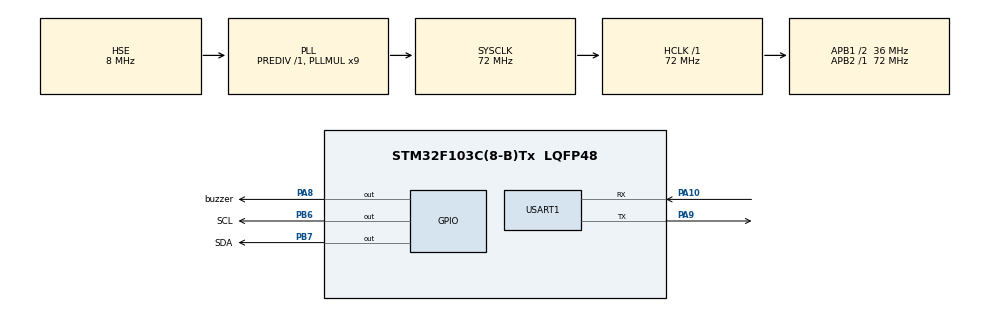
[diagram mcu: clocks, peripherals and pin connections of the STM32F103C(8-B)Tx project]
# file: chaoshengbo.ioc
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Dma.Request0=USART1_RX
Dma.Request1=USART1_TX
Dma.USART1_RX.0.Direction=DMA_PERIPH_TO_MEMORY
Dma.USART1_RX.0.Instance=DMA1_Channel5
Dma.USART1_RX.0.MemDataAlignment=DMA_MDATAALIGN_BYTE
Dma.USART1_RX.0.MemInc=DMA_MINC_ENABLE
Dma.USART1_RX.0.Mode=DMA_NORMAL
Dma.USART1_RX.0.PeriphDataAlignment=DMA_PDATAALIGN_BYTE
Dma.USART1_RX.0.PeriphInc=DMA_PINC_DISABLE
Dma.USART1_RX.0.Priority=DMA_PRIORITY_LOW
Dma.USART1_TX.1.Direction=DMA_MEMORY_TO_PERIPH
Dma.USART1_TX.1.Instance=DMA1_Channel4
Dma.USART1_TX.1.MemDataAlignment=DMA_MDATAALIGN_BYTE
Dma.USART1_TX.1.MemInc=DMA_MINC_ENABLE
Dma.USART1_TX.1.Mode=DMA_NORMAL
Dma.USART1_TX.1.PeriphDataAlignment=DMA_PDATAALIGN_BYTE
Dma.USART1_TX.1.PeriphInc=DMA_PINC_DISABLE
Dma.USART1_TX.1.Priority=DMA_PRIORITY_LOW
Mcu.Family=STM32F1
Mcu.Name=STM32F103C(8-B)Tx
Mcu.Package=LQFP48
NVIC.DMA1_Channel4_IRQn=true\:0\:0\:false\:false\:true\:false\:true\:true
NVIC.DMA1_Channel5_IRQn=true\:0\:0\:false\:false\:true\:false\:true\:true
NVIC.PriorityGroup=NVIC_PRIORITYGROUP_4
NVIC.TIM1_UP_IRQn=true\:1\:0\:true\:false\:true\:true\:true\:true
NVIC.USART1_IRQn=true\:2\:0\:true\:false\:true\:false\:true\:true
PA10.Mode=Asynchronous
PA10.Signal=USART1_RX
PA13.Mode=Serial_Wire
PA13.Signal=SYS_JTMS-SWDIO
PA14.Mode=Serial_Wire
PA14.Signal=SYS_JTCK-SWCLK
PA8.GPIO_Label=buzzer
PA8.PinState=GPIO_PIN_SET
PA8.Signal=GPIO_Output
PA9.Mode=Asynchronous
PA9.Signal=USART1_TX
PB6.GPIO_Label=SCL
PB6.GPIO_ModeDefaultOutputPP=GPIO_MODE_OUTPUT_OD
PB6.GPIO_PuPd=GPIO_NOPULL
PB6.PinState=GPIO_PIN_SET
PB6.Signal=GPIO_Output
PB7.GPIO_Label=SDA
PB7.GPIO_ModeDefaultOutputPP=GPIO_MODE_OUTPUT_OD
PB7.GPIO_PuPd=GPIO_NOPULL
PB7.PinState=GPIO_PIN_SET
PB7.Signal=GPIO_Output
PD0-OSC_IN.Mode=HSE-External-Oscillator
PD0-OSC_IN.Signal=RCC_OSC_IN
PD1-OSC_OUT.Mode=HSE-External-Oscillator
PD1-OSC_OUT.Signal=RCC_OSC_OUT
ProjectManager.HeapSize=0x200
ProjectManager.StackSize=0x400
ProjectManager.TargetToolchain=MDK-ARM V5.32
RCC.AHBFreq_Value=72000000
RCC.APB1CLKDivider=RCC_HCLK_DIV2
RCC.APB1Freq_Value=36000000
RCC.APB1TimFreq_Value=72000000
RCC.APB2Freq_Value=72000000
RCC.APB2TimFreq_Value=72000000
RCC.HCLKFreq_Value=72000000
RCC.PLLMUL=RCC_PLL_MUL9
RCC.PLLSourceVirtual=RCC_PLLSOURCE_HSE
RCC.SYSCLKFreq_VALUE=72000000
RCC.SYSCLKSource=RCC_SYSCLKSOURCE_PLLCLK
RCC.USBFreq_Value=72000000
TIM1.Period=1000-1
TIM1.Prescaler=72-1
USART1.VirtualMode=VM_ASYNC
VP_TIM1_VS_ClockSourceINT.Mode=Internal
board=custom

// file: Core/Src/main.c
/* USER CODE BEGIN Header */
/**
  ******************************************************************************
  * @file           : main.c
  * @brief          : Main program body
  ******************************************************************************
  * @attention
  *
  * Copyright (c) 2024 STMicroelectronics.
  * All rights reserved.
  *
  * This software is licensed under terms that can be found in the LICENSE file
  * in the root directory of this software component.
  * If no LICENSE file comes with this software, it is provided AS-IS.
  *
  ******************************************************************************
  */
/* USER CODE END Header */
#include "main.h"
#include "dma.h"
#include "tim.h"
#include "usart.h"
#include "gpio.h"

/* USER CODE BEGIN Includes */
//自己建立的头文件
#include "buzzer.h"
#include "ruanjianiic.h"

/* USER CODE END Includes */

void SystemClock_Config(void);

/* USER CODE BEGIN 0 */

//定时器中断函数
void HAL_TIM_PeriodElapsedCallback(TIM_HandleTypeDef *htim)
{
	if(htim->Instance == TIM1)
	{
		;
	}
}

/* USER CODE END 0 */

int main(void)
{

  /* MCU Configuration--------------------------------------------------------*/

  /* Reset of all peripherals, Initializes the Flash interface and the Systick. */
  HAL_Init();

  /* Configure the system clock */
  SystemClock_Config();

  /* Initialize all configured peripherals */
  MX_GPIO_Init();
  MX_DMA_Init();
  MX_USART1_UART_Init();
  MX_TIM1_Init();
  /* USER CODE BEGIN 2 */
	HAL_UART_Receive_DMA(&huart1, Rx_Buf, Rx_Max);
	__HAL_UART_ENABLE_IT(&huart1, UART_IT_IDLE);
	Set_Buzzer_State(1);//关闭蜂鸣器
	OLED_Init();
//	OLED_ShowChar(1,1, 'G');
//	OLED_ShowChar(1,2, 'B');
//	OLED_ShowString(2,1, "Hello World!");
//	OLED_ShowString(3,1, "Num= ");
//	OLED_ShowNum(3, 5, 1234, 4);
//  OLED_ShowChinese(1, 1, 1);
//	OLED_ShowChinese(1, 2, 2);
//	OLED_ShowChinese(1, 3, 3);
//	OLED_ShowChinese(1, 4, 4);
//	OLED_ShowChinese(1, 5, 5);
//  OLED_ShowChinese(2, 1, 6);
//	OLED_ShowChinese(2, 2, 7);
//	OLED_ShowChinese(2, 3, 8);
//	OLED_ShowChinese(2, 4, 9);
//	OLED_ShowChinese(2, 5, 10);
//  OLED_ShowChinese(3, 1, 11);
//	OLED_ShowChinese(3, 2, 12);
//	OLED_ShowChinese(3, 3, 13);
//	OLED_ShowChinese(3, 4, 14);
//	OLED_ShowChinese(3, 5, 15);
//  OLED_ShowChinese(4, 1, 16);
//	OLED_ShowChinese(4, 2, 17);
//	OLED_ShowChinese(4, 3, 18);
//	OLED_ShowChinese(4, 4, 19);
//	OLED_ShowChinese(4, 5, 20);
	OLED_ShowPicture(1);
  /* USER CODE END 2 */

  /* Infinite loop */
  while (1)
  {

  }
}

void SystemClock_Config(void)
{
  RCC_OscInitTypeDef RCC_OscInitStruct = {0};
  RCC_ClkInitTypeDef RCC_ClkInitStruct = {0};

  /** Initializes the RCC Oscillators according to the specified parameters
  * in the RCC_OscInitTypeDef structure.
  */
  RCC_OscInitStruct.OscillatorType = RCC_OSCILLATORTYPE_HSE;
  RCC_OscInitStruct.HSEState = RCC_HSE_ON;
  RCC_OscInitStruct.HSEPredivValue = RCC_HSE_PREDIV_DIV1;
  RCC_OscInitStruct.HSIState = RCC_HSI_ON;
  RCC_OscInitStruct.PLL.PLLState = RCC_PLL_ON;
  RCC_OscInitStruct.PLL.PLLSource = RCC_PLLSOURCE_HSE;
  RCC_OscInitStruct.PLL.PLLMUL = RCC_PLL_MUL9;
  if (HAL_RCC_OscConfig(&RCC_OscInitStruct) != HAL_OK)
  {
    Error_Handler();
  }

  /** Initializes the CPU, AHB and APB buses clocks
  */
  RCC_ClkInitStruct.ClockType = RCC_CLOCKTYPE_HCLK|RCC_CLOCKTYPE_SYSCLK
                              |RCC_CLOCKTYPE_PCLK1|RCC_CLOCKTYPE_PCLK2;
  RCC_ClkInitStruct.SYSCLKSource = RCC_SYSCLKSOURCE_PLLCLK;
  RCC_ClkInitStruct.AHBCLKDivider = RCC_SYSCLK_DIV1;
  RCC_ClkInitStruct.APB1CLKDivider = RCC_HCLK_DIV2;
  RCC_ClkInitStruct.APB2CLKDivider = RCC_HCLK_DIV1;

  if (HAL_RCC_ClockConfig(&RCC_ClkInitStruct, FLASH_LATENCY_2) != HAL_OK)
  {
    Error_Handler();
  }
}

void Error_Handler(void)
{
  __disable_irq();
  while (1)
  {
  }
}
